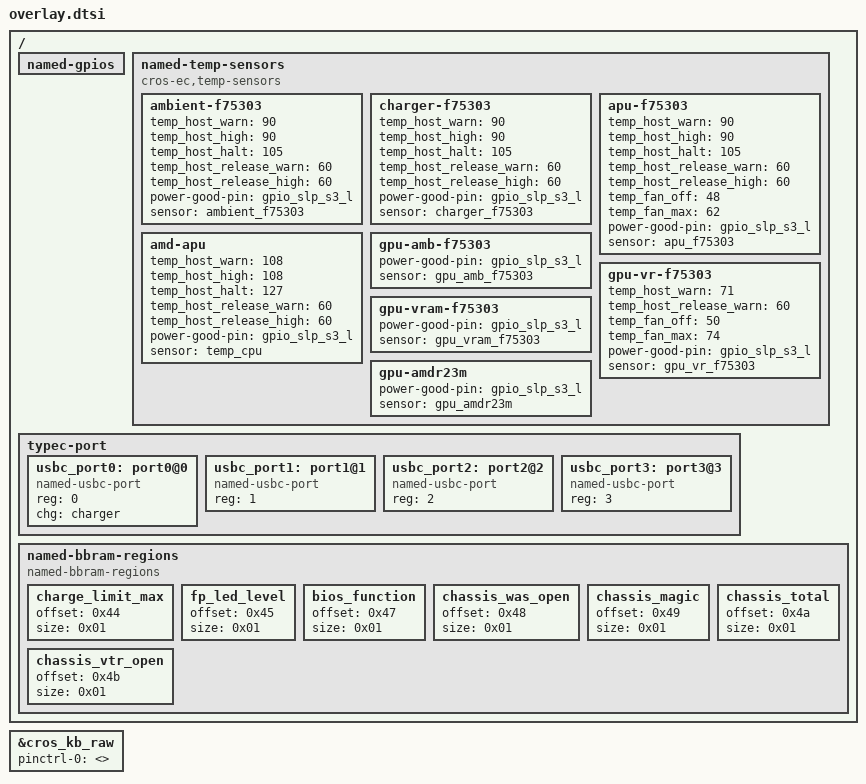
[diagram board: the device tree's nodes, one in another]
/* Copyright 2022 The ChromiumOS Authors
 * Use of this source code is governed by a BSD-style license that can be
 * found in the LICENSE file.
 */

/ {
	named-gpios {
		/* Lotus-specific GPIO customizations */
	};

	named-temp-sensors {
		compatible = "cros-ec,temp-sensors";
		ambient-f75303 {
			temp_host_warn = <90>;
			temp_host_high = <90>;
			temp_host_halt = <105>;
			temp_host_release_warn = <60>;
			temp_host_release_high = <60>;
			power-good-pin = <&gpio_slp_s3_l>;
			sensor = <&ambient_f75303>;
		};
		charger-f75303 {
			temp_host_warn = <90>;
			temp_host_high = <90>;
			temp_host_halt = <105>;
			temp_host_release_warn = <60>;
			temp_host_release_high = <60>;
			power-good-pin = <&gpio_slp_s3_l>;
			sensor = <&charger_f75303>;
		};
		apu-f75303 {
			temp_host_warn = <90>;
			temp_host_high = <90>;
			temp_host_halt = <105>;
			temp_host_release_warn = <60>;
			temp_host_release_high = <60>;
			temp_fan_off = <48>;
			temp_fan_max = <62>;
			power-good-pin = <&gpio_slp_s3_l>;
			sensor = <&apu_f75303>;
		};
		amd-apu {
			temp_host_warn = <108>;
			temp_host_high = <108>;
			temp_host_halt = <127>;
			temp_host_release_warn = <60>;
			temp_host_release_high = <60>;
			power-good-pin = <&gpio_slp_s3_l>;
			sensor = <&temp_cpu>;
		};
		gpu-amb-f75303 {
			power-good-pin = <&gpio_slp_s3_l>;
			sensor = <&gpu_amb_f75303>;
		};
		gpu-vr-f75303 {
			temp_host_warn = <71>;
			temp_host_release_warn = <60>;
			temp_fan_off = <50>;
			temp_fan_max = <74>;
			power-good-pin = <&gpio_slp_s3_l>;
			sensor = <&gpu_vr_f75303>;
		};
		gpu-vram-f75303 {
			power-good-pin = <&gpio_slp_s3_l>;
			sensor = <&gpu_vram_f75303>;
		};
		gpu-amdr23m {
			power-good-pin = <&gpio_slp_s3_l>;
			sensor = <&gpu_amdr23m>;
		};
	};

	typec-port {
		#address-cells = <1>;
		#size-cells = <0>;

		/*
		 * If the CHARGER_SINGLE_CHIP config is enabled, only
		 * one charger chip must be defined.
		 *
		 * In the Zephyer OS, the CONFIG_USB_PD_PORT_MAX_COUNT will check
		 * the device tree compatible "named-usbc-port"
		 */
		usbc_port0: port0@0 {
			compatible = "named-usbc-port";
			reg = <0>;
			chg = <&charger>;
		};
		usbc_port1: port1@1 {
			compatible = "named-usbc-port";
			reg = <1>;
		};
		usbc_port2: port2@2 {
			compatible = "named-usbc-port";
			reg = <2>;
		};
		usbc_port3: port3@3 {
			compatible = "named-usbc-port";
			reg = <3>;
		};
	};
	named-bbram-regions {
		compatible = "named-bbram-regions";
		charge_limit_max {
			offset = <0x44>;
			size = <0x01>;
		};
		fp_led_level {
			offset = <0x45>;
			size = <0x01>;
		};

		bios_function {
			offset = <0x47>;
			size = <0x01>;
		};
		chassis_was_open {
			offset = <0x48>;
			size = <0x01>;
		};
		chassis_magic {
			offset = <0x49>;
			size = <0x01>;
		};
		chassis_total {
			offset = <0x4a>;
			size = <0x01>;
		};
		chassis_vtr_open {
			offset = <0x4b>;
			size = <0x01>;
		};
	};
};

&cros_kb_raw {
	status = "okay";
	pinctrl-0 = <>;
	pinctrl-names = "default";
};

